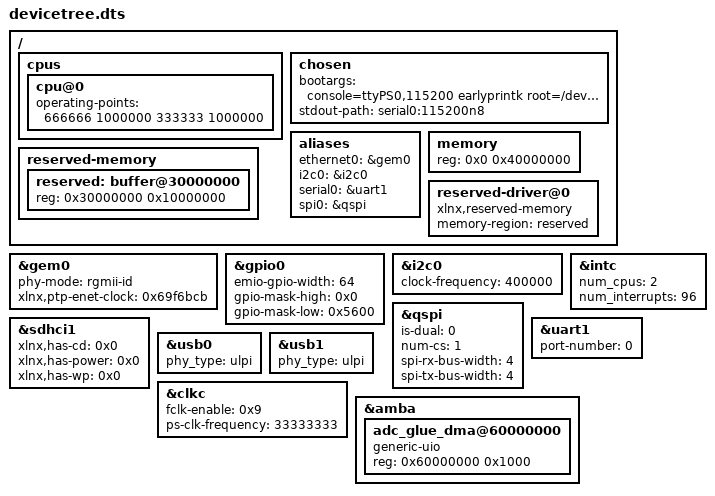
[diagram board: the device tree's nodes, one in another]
/dts-v1/;

/include/ "ext/zynq-7000.dtsi"

/ {
	cpus {
		cpu@0 {
			operating-points = <666666 1000000 333333 1000000>;
		};
	};
};
&gem0 {
	phy-mode = "rgmii-id";
	status = "okay";
	xlnx,ptp-enet-clock = <0x69f6bcb>;
};
&gpio0 {
	emio-gpio-width = <64>;
	gpio-mask-high = <0x0>;
	gpio-mask-low = <0x5600>;
};
&i2c0 {
	clock-frequency = <400000>;
	status = "okay";
};
&intc {
	num_cpus = <2>;
	num_interrupts = <96>;
};
&qspi {
	is-dual = <0>;
	num-cs = <1>;
	spi-rx-bus-width = <4>;
	spi-tx-bus-width = <4>;
	status = "okay";
};
&sdhci1 {
	status = "okay";
	xlnx,has-cd = <0x0>;
	xlnx,has-power = <0x0>;
	xlnx,has-wp = <0x0>;
};
&uart1 {
	device_type = "serial";
	port-number = <0>;
	status = "okay";
};
&usb0 {
	phy_type = "ulpi";
	status = "okay";
};
&usb1 {
	phy_type = "ulpi";
	status = "okay";
};
&clkc {
	fclk-enable = <0x1>;
	ps-clk-frequency = <33333333>;
};

/ {
	chosen {
		bootargs = "console=ttyPS0,115200 earlyprintk root=/dev/mmcblk0p2 rootfstype=ext4 rw rootwait earlycon";
		stdout-path = "serial0:115200n8";
	};
	aliases {
		ethernet0 = &gem0;
		i2c0 = &i2c0;
		serial0 = &uart1;
		spi0 = &qspi;
	};
	memory {
		device_type = "memory";
		reg = <0x0 0x40000000>;
	};

	reserved-memory {
		#address-cells = <1>;
		#size-cells = <1>;
		ranges;

		reserved: buffer@30000000 {
			reg = <0x30000000 0x10000000>;
		};
	};

	reserved-driver@0 {
		compatible = "xlnx,reserved-memory";
		memory-region = <&reserved>;
	};
};

&amba {
	adc_glue_dma@60000000 {
		compatible = "generic-uio";
		reg = < 0x60000000 0x1000 >;
	};
};

&clkc {
	fclk-enable = <0x9>;
};
